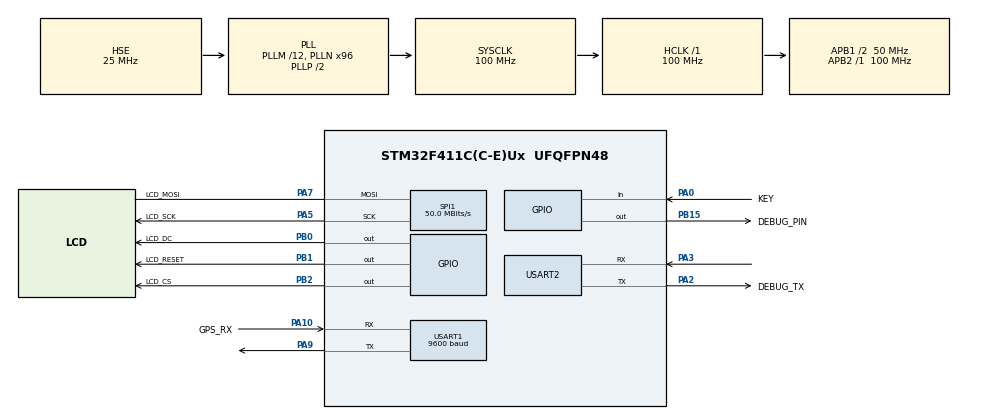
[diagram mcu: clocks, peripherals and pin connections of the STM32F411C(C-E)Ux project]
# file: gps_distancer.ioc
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FREERTOS.BinarySemaphores01=lcd_sem,Dynamic,NULL;printer_sem,Dynamic,NULL
FREERTOS.Queues01=gps_chars,256,uint8_t,0,Dynamic,NULL,NULL;gps_msg,16,GPS_MSG,0,Dynamic,NULL,NULL;printer_q,10,DEBUG_MSG_LEN,0,Dynamic,NULL,NULL;gps_points,32,GPS_POINT,0,Dynamic,NULL,NULL
FREERTOS.Tasks01=GPS_Receiver,24,256,StartGPSReceiver,Default,NULL,Dynamic,NULL,NULL;Parser_Task,24,256,Start_Parser,Default,NULL,Dynamic,NULL,NULL;LCD_Updater,24,256,Start_lcd,Default,NULL,Dynamic,NULL,NULL;Print_Task,24,256,Start_printer,Default,NULL,Dynamic,NULL,NULL;LCD_Idel,8,256,Start_lcd_idel,Default,NULL,Dynamic,NULL,NULL
FREERTOS.configENABLE_FPU=1
FREERTOS.configTOTAL_HEAP_SIZE=30720
Mcu.Family=STM32F4
Mcu.Name=STM32F411C(C-E)Ux
Mcu.Package=UFQFPN48
NVIC.PriorityGroup=NVIC_PRIORITYGROUP_4
NVIC.TIM5_IRQn=true\:15\:0\:false\:false\:true\:false\:false\:true\:true
NVIC.TimeBase=TIM5_IRQn
NVIC.TimeBaseIP=TIM5
NVIC.USART1_IRQn=true\:5\:0\:false\:false\:true\:true\:true\:true\:true
PA0-WKUP.GPIO_Label=KEY
PA0-WKUP.GPIO_PuPd=GPIO_PULLUP
PA0-WKUP.Signal=GPIO_Input
PA10.GPIO_Label=GPS_RX
PA10.Mode=Asynchronous
PA10.Signal=USART1_RX
PA2.GPIO_Label=DEBUG_TX
PA2.Mode=Asynchronous
PA2.Signal=USART2_TX
PA3.Mode=Asynchronous
PA3.Signal=USART2_RX
PA5.GPIO_Label=LCD_SCK
PA5.Mode=Simplex_Bidirectional_Master
PA5.Signal=SPI1_SCK
PA7.GPIO_Label=LCD_MOSI
PA7.Mode=Simplex_Bidirectional_Master
PA7.Signal=SPI1_MOSI
PA9.Mode=Asynchronous
PA9.Signal=USART1_TX
PB0.GPIO_Label=LCD_DC
PB0.Signal=GPIO_Output
PB1.GPIO_Label=LCD_RESET
PB1.Signal=GPIO_Output
PB15.GPIO_Label=DEBUG_PIN
PB15.GPIO_Speed=GPIO_SPEED_FREQ_VERY_HIGH
PB15.Signal=GPIO_Output
PB2.GPIO_Label=LCD_CS
PB2.Signal=GPIO_Output
PH0\ -\ OSC_IN.Mode=HSE-External-Oscillator
PH0\ -\ OSC_IN.Signal=RCC_OSC_IN
PH1\ -\ OSC_OUT.Mode=HSE-External-Oscillator
PH1\ -\ OSC_OUT.Signal=RCC_OSC_OUT
ProjectManager.HeapSize=0x200
ProjectManager.StackSize=0x400
ProjectManager.TargetToolchain=Makefile
RCC.48MHZClocksFreq_Value=50000000
RCC.AHBFreq_Value=100000000
RCC.APB1CLKDivider=RCC_HCLK_DIV2
RCC.APB1Freq_Value=50000000
RCC.APB1TimFreq_Value=100000000
RCC.APB2Freq_Value=100000000
RCC.APB2TimFreq_Value=100000000
RCC.CortexFreq_Value=100000000
RCC.HCLKFreq_Value=100000000
RCC.HSE_VALUE=25000000
RCC.HSI_VALUE=16000000
RCC.LSE_VALUE=32768
RCC.PLLM=12
RCC.PLLN=96
RCC.PLLSourceVirtual=RCC_PLLSOURCE_HSE
RCC.SYSCLKFreq_VALUE=100000000
RCC.SYSCLKSource=RCC_SYSCLKSOURCE_PLLCLK
RCC.VCOOutputFreq_Value=200000000
SPI1.BaudRatePrescaler=SPI_BAUDRATEPRESCALER_2
SPI1.CalculateBaudRate=50.0 MBits/s
SPI1.Direction=SPI_DIRECTION_1LINE
SPI1.Mode=SPI_MODE_MASTER
SPI1.VirtualType=VM_MASTER
USART1.BaudRate=9600
USART1.VirtualMode=VM_ASYNC
USART2.VirtualMode=VM_ASYNC
VP_FREERTOS_VS_CMSIS_V2.Mode=CMSIS_V2
VP_SYS_VS_tim5.Mode=TIM5
board=custom

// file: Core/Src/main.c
/* USER CODE BEGIN Header */
/**
  ******************************************************************************
  * @file           : main.c
  * @brief          : Main program body
  ******************************************************************************
  * @attention
  *
  * Copyright (c) 2024 STMicroelectronics.
  * All rights reserved.
  *
  * This software is licensed under terms that can be found in the LICENSE file
  * in the root directory of this software component.
  * If no LICENSE file comes with this software, it is provided AS-IS.
  *
  ******************************************************************************
  */
/* USER CODE END Header */
#include "main.h"
#include "cmsis_os2.h"

/* USER CODE BEGIN Includes */
#include "gps.h"
#include <string.h>
/* USER CODE END Includes */

SPI_HandleTypeDef hspi1;

UART_HandleTypeDef huart1;
UART_HandleTypeDef huart2;

/* Definitions for GPS_Receiver */
osThreadId_t GPS_ReceiverHandle;
const osThreadAttr_t GPS_Receiver_attributes = {
  .name = "GPS_Receiver",
  .stack_size = 256 * 4,
  .priority = (osPriority_t) osPriorityNormal,
};
/* Definitions for Parser_Task */
osThreadId_t Parser_TaskHandle;
const osThreadAttr_t Parser_Task_attributes = {
  .name = "Parser_Task",
  .stack_size = 256 * 4,
  .priority = (osPriority_t) osPriorityNormal,
};
/* Definitions for LCD_Updater */
osThreadId_t LCD_UpdaterHandle;
const osThreadAttr_t LCD_Updater_attributes = {
  .name = "LCD_Updater",
  .stack_size = 256 * 4,
  .priority = (osPriority_t) osPriorityHigh,
};
/* Definitions for Print_Task */
osThreadId_t Print_TaskHandle;
const osThreadAttr_t Print_Task_attributes = {
  .name = "Print_Task",
  .stack_size = 256 * 4,
  .priority = (osPriority_t) osPriorityNormal,
};
/* Definitions for LCD_Idel */
osThreadId_t LCD_IdelHandle;
const osThreadAttr_t LCD_Idel_attributes = {
  .name = "LCD_Idel",
  .stack_size = 256 * 4,
  .priority = (osPriority_t) osPriorityLow,
};
/* Definitions for gps_chars */
osMessageQueueId_t gps_charsHandle;
const osMessageQueueAttr_t gps_chars_attributes = {
  .name = "gps_chars"
};
/* Definitions for gps_msg */
osMessageQueueId_t gps_msgHandle;
const osMessageQueueAttr_t gps_msg_attributes = {
  .name = "gps_msg"
};
/* Definitions for printer_q */
osMessageQueueId_t printer_qHandle;
const osMessageQueueAttr_t printer_q_attributes = {
  .name = "printer_q"
};
/* Definitions for gps_points */
osMessageQueueId_t gps_pointsHandle;
const osMessageQueueAttr_t gps_points_attributes = {
  .name = "gps_points"
};
/* Definitions for lcd_sem */
osSemaphoreId_t lcd_semHandle;
const osSemaphoreAttr_t lcd_sem_attributes = {
  .name = "lcd_sem"
};
/* Definitions for printer_sem */
osSemaphoreId_t printer_semHandle;
const osSemaphoreAttr_t printer_sem_attributes = {
  .name = "printer_sem"
};

void SystemClock_Config(void);
static void MX_GPIO_Init(void);
static void MX_SPI1_Init(void);
static void MX_USART1_UART_Init(void);
static void MX_USART2_UART_Init(void);

int main(void)
{

  /* MCU Configuration--------------------------------------------------------*/

  /* Reset of all peripherals, Initializes the Flash interface and the Systick. */
  HAL_Init();

  /* Configure the system clock */
  SystemClock_Config();

  /* Initialize all configured peripherals */
  MX_GPIO_Init();
  MX_SPI1_Init();
  MX_USART1_UART_Init();
  MX_USART2_UART_Init();

  /* Init scheduler */
  osKernelInitialize();

  /* Create the semaphores(s) */
  /* creation of lcd_sem */
  lcd_semHandle = osSemaphoreNew(1, 1, &lcd_sem_attributes);

  /* creation of printer_sem */
  printer_semHandle = osSemaphoreNew(1, 1, &printer_sem_attributes);

  /* Create the queue(s) */
  /* creation of gps_chars */
  gps_charsHandle = osMessageQueueNew (32, sizeof(uint8_t), &gps_chars_attributes);

  /* creation of gps_msg */
  gps_msgHandle = osMessageQueueNew (8, sizeof(GPS_MSG), &gps_msg_attributes);

  /* creation of printer_q */
  printer_qHandle = osMessageQueueNew (10, DEBUG_MSG_LEN, &printer_q_attributes);

  /* creation of gps_points */
  gps_pointsHandle = osMessageQueueNew (32, sizeof(GPS_POINT), &gps_points_attributes);

  /* Create the thread(s) */
  /* creation of GPS_Receiver */
  GPS_ReceiverHandle = osThreadNew(StartGPSReceiver, NULL, &GPS_Receiver_attributes);

  /* creation of Parser_Task */
  Parser_TaskHandle = osThreadNew(Start_Parser, NULL, &Parser_Task_attributes);

  /* creation of LCD_Updater */
  LCD_UpdaterHandle = osThreadNew(Start_lcd, NULL, &LCD_Updater_attributes);

  /* creation of Print_Task */
  Print_TaskHandle = osThreadNew(Start_printer, NULL, &Print_Task_attributes);

  /* creation of LCD_Idel */
  LCD_IdelHandle = osThreadNew(Start_lcd_idel, NULL, &LCD_Idel_attributes);

  /* Start scheduler */
  osKernelStart();

  /* We should never get here as control is now taken by the scheduler */
  /* Infinite loop */
  while (1)
  {

  }
}

void SystemClock_Config(void)
{
  RCC_OscInitTypeDef RCC_OscInitStruct = {0};
  RCC_ClkInitTypeDef RCC_ClkInitStruct = {0};

  /** Configure the main internal regulator output voltage
  */
  __HAL_RCC_PWR_CLK_ENABLE();
  __HAL_PWR_VOLTAGESCALING_CONFIG(PWR_REGULATOR_VOLTAGE_SCALE1);

  /** Initializes the RCC Oscillators according to the specified parameters
  * in the RCC_OscInitTypeDef structure.
  */
  RCC_OscInitStruct.OscillatorType = RCC_OSCILLATORTYPE_HSE;
  RCC_OscInitStruct.HSEState = RCC_HSE_ON;
  RCC_OscInitStruct.PLL.PLLState = RCC_PLL_ON;
  RCC_OscInitStruct.PLL.PLLSource = RCC_PLLSOURCE_HSE;
  RCC_OscInitStruct.PLL.PLLM = 12;
  RCC_OscInitStruct.PLL.PLLN = 96;
  RCC_OscInitStruct.PLL.PLLP = RCC_PLLP_DIV2;
  RCC_OscInitStruct.PLL.PLLQ = 4;
  if (HAL_RCC_OscConfig(&RCC_OscInitStruct) != HAL_OK)
  {
    Error_Handler();
  }

  /** Initializes the CPU, AHB and APB buses clocks
  */
  RCC_ClkInitStruct.ClockType = RCC_CLOCKTYPE_HCLK|RCC_CLOCKTYPE_SYSCLK
                              |RCC_CLOCKTYPE_PCLK1|RCC_CLOCKTYPE_PCLK2;
  RCC_ClkInitStruct.SYSCLKSource = RCC_SYSCLKSOURCE_PLLCLK;
  RCC_ClkInitStruct.AHBCLKDivider = RCC_SYSCLK_DIV1;
  RCC_ClkInitStruct.APB1CLKDivider = RCC_HCLK_DIV2;
  RCC_ClkInitStruct.APB2CLKDivider = RCC_HCLK_DIV1;

  if (HAL_RCC_ClockConfig(&RCC_ClkInitStruct, FLASH_LATENCY_3) != HAL_OK)
  {
    Error_Handler();
  }
}

static void MX_SPI1_Init(void)
{

  /* SPI1 parameter configuration*/
  hspi1.Instance = SPI1;
  hspi1.Init.Mode = SPI_MODE_MASTER;
  hspi1.Init.Direction = SPI_DIRECTION_1LINE;
  hspi1.Init.DataSize = SPI_DATASIZE_8BIT;
  hspi1.Init.CLKPolarity = SPI_POLARITY_LOW;
  hspi1.Init.CLKPhase = SPI_PHASE_1EDGE;
  hspi1.Init.NSS = SPI_NSS_SOFT;
  hspi1.Init.BaudRatePrescaler = SPI_BAUDRATEPRESCALER_2;
  hspi1.Init.FirstBit = SPI_FIRSTBIT_MSB;
  hspi1.Init.TIMode = SPI_TIMODE_DISABLE;
  hspi1.Init.CRCCalculation = SPI_CRCCALCULATION_DISABLE;
  hspi1.Init.CRCPolynomial = 10;
  if (HAL_SPI_Init(&hspi1) != HAL_OK)
  {
    Error_Handler();
  }

}

static void MX_USART1_UART_Init(void)
{

  huart1.Instance = USART1;
  huart1.Init.BaudRate = 9600;
  huart1.Init.WordLength = UART_WORDLENGTH_8B;
  huart1.Init.StopBits = UART_STOPBITS_1;
  huart1.Init.Parity = UART_PARITY_NONE;
  huart1.Init.Mode = UART_MODE_TX_RX;
  huart1.Init.HwFlowCtl = UART_HWCONTROL_NONE;
  huart1.Init.OverSampling = UART_OVERSAMPLING_16;
  if (HAL_UART_Init(&huart1) != HAL_OK)
  {
    Error_Handler();
  }

}

static void MX_USART2_UART_Init(void)
{

  huart2.Instance = USART2;
  huart2.Init.BaudRate = 115200;
  huart2.Init.WordLength = UART_WORDLENGTH_8B;
  huart2.Init.StopBits = UART_STOPBITS_1;
  huart2.Init.Parity = UART_PARITY_NONE;
  huart2.Init.Mode = UART_MODE_TX_RX;
  huart2.Init.HwFlowCtl = UART_HWCONTROL_NONE;
  huart2.Init.OverSampling = UART_OVERSAMPLING_16;
  if (HAL_UART_Init(&huart2) != HAL_OK)
  {
    Error_Handler();
  }

}

static void MX_GPIO_Init(void)
{
  GPIO_InitTypeDef GPIO_InitStruct = {0};

  /* GPIO Ports Clock Enable */
  __HAL_RCC_GPIOH_CLK_ENABLE();
  __HAL_RCC_GPIOA_CLK_ENABLE();
  __HAL_RCC_GPIOB_CLK_ENABLE();

  /*Configure GPIO pin Output Level */
  HAL_GPIO_WritePin(GPIOB, LCD_DC_Pin|LCD_RESET_Pin|LCD_CS_Pin|DEBUG_PIN_Pin, GPIO_PIN_RESET);

  /*Configure GPIO pin : KEY_Pin */
  GPIO_InitStruct.Pin = KEY_Pin;
  GPIO_InitStruct.Mode = GPIO_MODE_INPUT;
  GPIO_InitStruct.Pull = GPIO_PULLUP;
  HAL_GPIO_Init(KEY_GPIO_Port, &GPIO_InitStruct);

  /*Configure GPIO pins : LCD_DC_Pin LCD_RESET_Pin LCD_CS_Pin */
  GPIO_InitStruct.Pin = LCD_DC_Pin|LCD_RESET_Pin|LCD_CS_Pin;
  GPIO_InitStruct.Mode = GPIO_MODE_OUTPUT_PP;
  GPIO_InitStruct.Pull = GPIO_NOPULL;
  GPIO_InitStruct.Speed = GPIO_SPEED_FREQ_LOW;
  HAL_GPIO_Init(GPIOB, &GPIO_InitStruct);

  /*Configure GPIO pin : DEBUG_PIN_Pin */
  GPIO_InitStruct.Pin = DEBUG_PIN_Pin;
  GPIO_InitStruct.Mode = GPIO_MODE_OUTPUT_PP;
  GPIO_InitStruct.Pull = GPIO_NOPULL;
  GPIO_InitStruct.Speed = GPIO_SPEED_FREQ_VERY_HIGH;
  HAL_GPIO_Init(DEBUG_PIN_GPIO_Port, &GPIO_InitStruct);

}

void HAL_TIM_PeriodElapsedCallback(TIM_HandleTypeDef *htim)
{
  if (htim->Instance == TIM5) {
    HAL_IncTick();
  }
}

void Error_Handler(void)
{
  __disable_irq();
  while (1)
  {
  }
}
